# MKW38A4 register map
Vendor: NXP Semiconductors; Series: Kinetis_W; File version: 1.6
CPU: CM0PLUS r0p0, little endian, no MPU, no FPU, VTOR, 2 interrupt priority bits
Registers are 32-bit, read-write, no defined reset value unless marked. A register's access mark holds for its fields unless they carry their own. Offsets are from the block's base; [hi:lo] are bit positions; {n}, {i} and the like mark numbered series; 'fields as' and 'values as' point back to an identical list.

## SIM — System Integration Module
Base 0x40047000; register names take the prefix SIM_
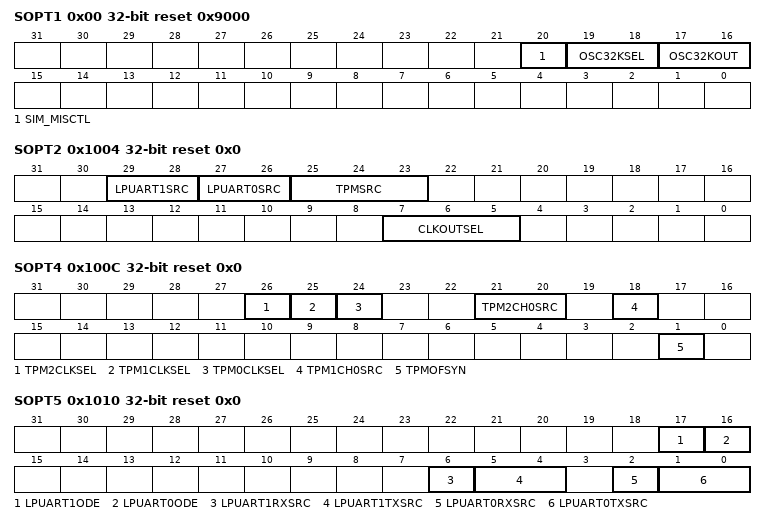
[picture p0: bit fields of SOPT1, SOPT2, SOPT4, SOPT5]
0x00 SOPT1 reset 0x9000 — System Options Register 1
  [20] SIM_MISCTL — This bit controls the function of BLE_RF_ACTIVE.
    0=Chip low power mode output to PAD; 1=Bluetooth LE active output to PAD
  [19:18] OSC32KSEL — 32K Oscillator Clock Select
    0=32kHz oscillator (OSC32KCLK); 2=RTC_CLKIN; 3=LPO 1kHz
  [17:16] OSC32KOUT — 32K oscillator clock output
    0=ERCLK32K is not output; 1=ERCLK32K is output on PTB3
0x1004 SOPT2 reset 0x0 — System Options Register 2
  [29:28] LPUART1SRC — LPUART1 Clock Source Select
    0=Clock disabled; 1=MCGFLLCLK clock; 2=OSCERCLK clock; 3=MCGIRCLK clock
  [27:26] LPUART0SRC — LPUART0 Clock Source Select
    values as LPUART1SRC
  [25:23] TPMSRC — TPM Clock Source Select
    0=Clock disabled; 1=MCGFLLCLK clock; 2=OSCERCLK clock; 3=MCGIRCLK clock; 4=LANT_SW
  [7:5] CLKOUTSEL — CLKOUT select
    0=OSCERCLK DIV2; 1=OSCERCLK DIV4; 2=Bus clock; 3=LPO clock 1 kHz; 4=MCGIRCLK; 5=OSCERCLK DIV8; 6=OSCERCLK
0x100C SOPT4 reset 0x0 — System Options Register 4
  [26] TPM2CLKSEL — TPM2 External Clock Pin Select
    0=TPM2 external clock driven by TPM_CLKIN0 pin; 1=TPM2 external clock driven by TPM_CLKIN1 pin
  [25] TPM1CLKSEL — TPM1 External Clock Pin Select
    0=TPM1 external clock driven by TPM_CLKIN0 pin; 1=TPM1 external clock driven by TPM_CLKIN1 pin
  [24] TPM0CLKSEL — TPM0 External Clock Pin Select
    0=TPM0 external clock driven by TPM_CLKIN0 pin; 1=TPM0 external clock driven by TPM_CLKIN1 pin
  [21:20] TPM2CH0SRC — TPM2 Channel 0 Input Capture Source Select
    0=TPM2_CH0 signal; 1=CMP0 output; 2=Radio time-of-flight timestamp trigger
  [18] TPM1CH0SRC — TPM1 Channel 0 Input Capture Source Select
    0=TPM1_CH0 signal; 1=CMP0 output
  [1] TPMOFSYN
    0=Enable TPM1 overflow output to TPM0 and TPM2 overflow in; 1=Disable TPM1 overflow output to TPM0 and TPM2 overflow in
0x1010 SOPT5 reset 0x0 — System Options Register 5
  [17] LPUART1ODE — LPUART1 Open Drain Enable
    0=Open drain is disabled on LPUART1; 1=Open drain is enabled on LPUART1
  [16] LPUART0ODE — LPUART0 Open Drain Enable
    0=Open drain is disabled on LPUART0; 1=Open drain is enabled on LPUART0
  [6] LPUART1RXSRC — LPUART1 Receive Data Source Select
    0=LPUART1_RX pin; 1=CMP0 output
  [5:4] LPUART1TXSRC — LPUART1 Transmit Data Source Select
    0=LPUART1_TX pin; 1=LPUART1_TX pin modulated with TPM1 channel 0 output; 2=LPUART1_TX pin modulated with TPM2 channel 0 output
  [2] LPUART0RXSRC — LPUART0 Receive Data Source Select
    0=LPUART_RX pin; 1=CMP0 output
  [1:0] LPUART0TXSRC — LPUART0 Transmit Data Source Select
    0=LPUART0_TX pin; 1=LPUART0_TX pin modulated with TPM1 channel 0 output; 2=LPUART0_TX pin modulated with TPM2 channel 0 output
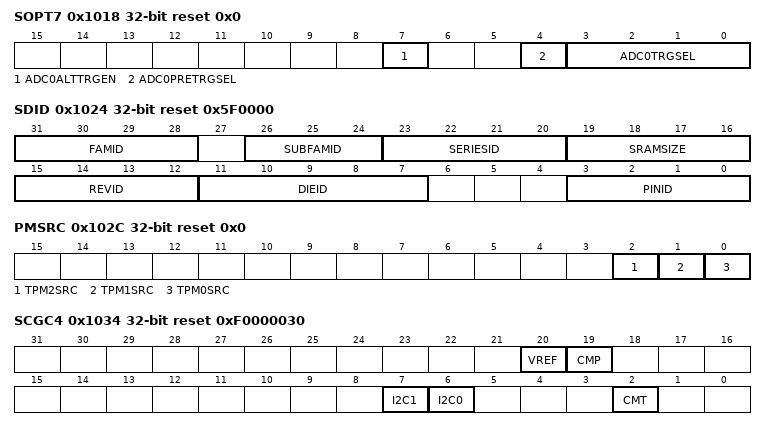
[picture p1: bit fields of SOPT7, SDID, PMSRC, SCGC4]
0x1018 SOPT7 reset 0x0 — System Options Register 7
  [7] ADC0ALTTRGEN — ADC0 Alternate Trigger Enable
    0=ADC ADHWT trigger comes from TPM1 channel 0 and channel1. Prior to the assertion of TPM1 channel 0, a pre-trigger pulse will be sent to ADHWTSA to initiate an ADC acquisition using ADCx_SC1A configuration and store ADC conversion in ADCx_RA Register. Prior to the assertion of TPM1 channel 1 a pre-trigger pulse will be sent to ADHWTSB to initiate an ADC acquisition using ADCx_SC1Bconfiguration and store ADC conversion in ADCx_RB Register.; 1=ADC ADHWT trigger comes from a peripheral event selected by ADC0TRGSEL bits.ADC0PRETRGSEL bit will select the optional ADHWTSA or ADHWTSB select lines for choosing the ADCx_SC1x config and ADCx_Rx result regsiter to store the ADC conversion
  [4] ADC0PRETRGSEL — ADC0 Pretrigger Select
    0=Pre-trigger ADHDWTSA is selected, thus ADC0 will use ADC0_SC1A configuration for the next ADC conversion and store the result in ADC0_RA register; 1=Pre-trigger ADHDWTSB is selected, thus ADC0 will use ADC0_SC1B configuration for the next ADC conversion and store the result in ADC0_RB register
  [3:0] ADC0TRGSEL — ADC0 Trigger Select
    0=External trigger pin input (EXTRG_IN); 1=CMP0 output; 4=PIT trigger 0; 5=PIT trigger 1; 8=TPM0 overflow; 9=TPM1 overflow; 10=TPM2 overflow; 12=RTC alarm interrupt and RTC seconds interrupt; 13=RTC seconds; 14=LPTMR0 trigger; 15=Radio TSM
0x1024 SDID ro reset 0x5F0000 — System Device Identification Register
  [31:28] FAMID — Kinetis family ID
    3=KW3x Family (BTLE)
  [26:24] SUBFAMID — Kinetis Sub-Family ID.
    7=KWx9 Sub family; 6=KWx7 Subfamily; 5=KWx8 Subfamily
  [23:20] SERIESID — Kinetis Series ID
    5=KW family
  [19:16] SRAMSIZE — System SRAM Size
    7=64 KB
  [15:12] REVID — Device Revision Number
  [11:7] DIEID — Device Die Number
  [3:0] PINID — Pin count Identification
    3=40-pin; 4=48-pin (LGA); 5=48-pin (wettable flank)
0x102C PMSRC reset 0x0 — Peripheral Module Soft Reset Control Register(SIM_PMSRC)
  [2] TPM2SRC wo — TPM2 Soft Reset Control
  [1] TPM1SRC wo — TPM1 Soft Reset Control
  [0] TPM0SRC wo — TPM0 Soft Reset Control
0x1034 SCGC4 reset 0xF0000030 — System Clock Gating Control Register 4
  [all] fields
    0=Clock disabled; 1=Clock enabled
  [20] VREF — VREF Clock Gate Control
  [19] CMP — Comparator Clock Gate Control
  [7] I2C1 — I2C1 Clock Gate Control
  [6] I2C0 — I2C0 Clock Gate Control
  [2] CMT — CMT Clock Gate Control
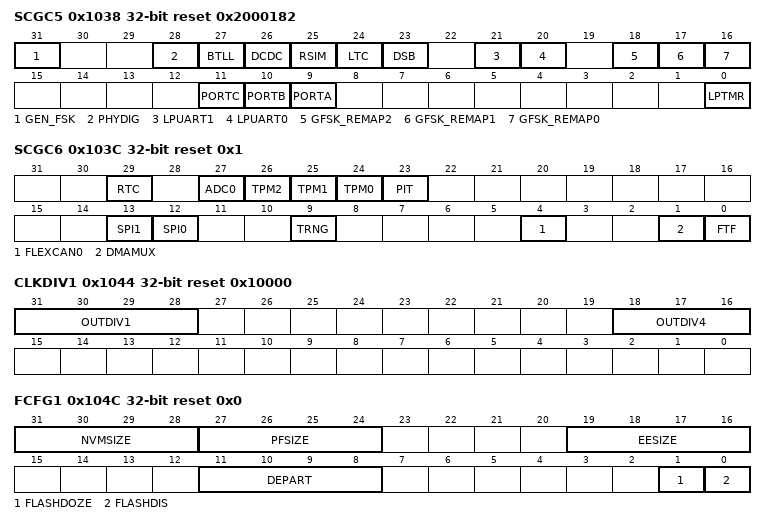
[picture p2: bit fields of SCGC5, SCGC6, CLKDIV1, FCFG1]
0x1038 SCGC5 reset 0x2000182 — System Clock Gating Control Register 5
  [31] GEN_FSK — Generic FSK enabled
    0=GFSK CGC bit disabled; 1=GFSK CGC bit enabled
  [28] PHYDIG — PHY Digital Clock Gate Control
    0=Clock disabled; 1=Clock enabled
  [27] BTLL — BTLL System Clock Gate Control
    0=Clock disabled; 1=Clock enabled
  [26] DCDC — DCDC Clock Gate Control
    0=Clock disabled; 1=Clock enabled
  [25] RSIM ro — RSIM Clock Gate Control
  [24] LTC — LTC Clock Gate Control
    0=Clock disabled; 1=Clock enabled
  [23] DSB — Data Stream Buffer Clock Gate Control
    0=Clock disabled; 1=Clock enabled
  [21] LPUART1 — LPUART1 Clock Gate Control
    0=Clock disabled; 1=Clock enabled
  [20] LPUART0 — LPUART0 Clock Gate Control
    0=Clock disabled; 1=Clock enabled
  [18] GFSK_REMAP2 — GFSK Remap2 Clock Gate Control
    0=Clock disabled; 1=Clock enabled
  [17] GFSK_REMAP1 — GFSK Remap1 Clock Gate Control
    0=Clock disabled; 1=Clock enabled
  [16] GFSK_REMAP0 — GFSK Remap0 Clock Gate Control
    0=Clock disabled; 1=Clock enabled
  [11] PORTC — Port C Clock Gate Control
    0=Clock disabled; 1=Clock enabled
  [10] PORTB — Port B Clock Gate Control
    0=Clock disabled; 1=Clock enabled
  [9] PORTA — Port A Clock Gate Control
    0=Clock disabled; 1=Clock enabled
  [0] LPTMR — Low Power Timer Access Control
    0=Access disabled; 1=Access enabled
0x103C SCGC6 reset 0x1 — System Clock Gating Control Register 6
  [29] RTC — RTC Access Control
    0=Access and interrupts disabled; 1=Access and interrupts enabled
  [27] ADC0 — ADC0 Clock Gate Control
    0=Clock disabled; 1=Clock enabled
  [26] TPM2 — TPM2 Clock Gate Control
    0=Clock disabled; 1=Clock enabled
  [25] TPM1 — TPM1 Clock Gate Control
    0=Clock disabled; 1=Clock enabled
  [24] TPM0 — TPM0 Clock Gate Control
    0=Clock disabled; 1=Clock enabled
  [23] PIT — PIT Clock Gate Control
    0=Clock disabled; 1=Clock enabled
  [13] SPI1 — SPI1 Clock Gate Control
    0=Clock disabled; 1=Clock enabled
  [12] SPI0 — SPI0 Clock Gate Control
    0=Clock disabled; 1=Clock enabled
  [9] TRNG — TRNG Clock Gate Control
    0=Clock disabled; 1=Clock enabled
  [4] FLEXCAN0 — FLEXCAN0 Clock Gate Control
    0=Clock disabled; 1=Clock enabled
  [1] DMAMUX — DMA Mux Clock Gate Control
    0=Clock disabled; 1=Clock enabled
  [0] FTF — Flash Memory Clock Gate Control
    0=Clock disabled; 1=Clock enabled
0x1040 SCGC7 reset 0x100 — System Clock Gating Control Register 7
  [8] DMA — DMA Clock Gate Control
    0=Clock disabled; 1=Clock enabled
0x1044 CLKDIV1 reset 0x10000 — System Clock Divider Register 1
  [31:28] OUTDIV1 — Clock 1 Output Divider value
    {v}=Divide-by-{v+1} (v=0..15)
  [18:16] OUTDIV4 — Clock 4 Output Divider value
    {v}=Divide-by-{v+1} (v=0..7)
0x104C FCFG1 reset 0x0 (reset mask 0xF0F0FF) — Flash Configuration Register 1
  [31:28] NVMSIZE ro — FlexNVM Size
    0=0 KB; 9=256 KB, 16 KB protection region; 15=256 KB, 16 KB protection region
  [27:24] PFSIZE ro — Program Flash Size
    9=256 KB of program flash memory; 11=512 KB of program flash memory
  [19:16] EESIZE ro — EEPROM Size
    1=8 KB; 2=4 KB; 3=2 KB; 4=1 KB; 5=512 bytes; 6=256 bytes; 7=128 bytes; 8=64 bytes; 9=32 bytes
  [11:8] DEPART ro — FlexNVM partition
  [1] FLASHDOZE
    0=Flash remains enabled during Doze mode; 1=Flash is disabled for the duration of Doze mode
  [0] FLASHDIS — Flash Disable
    0=Flash is enabled; 1=Flash is disabled
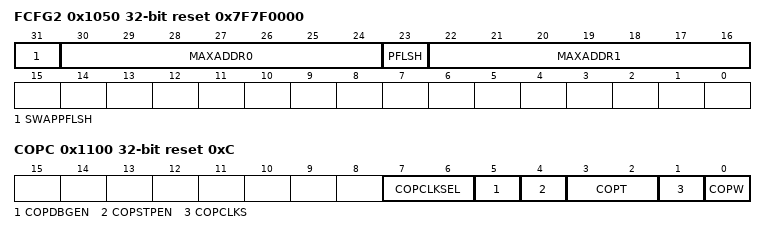
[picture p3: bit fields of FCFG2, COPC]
0x1050 FCFG2 ro reset 0x7F7F0000 — Flash Configuration Register 2
  [31] SWAPPFLSH — Swap program flash
    0=Swap is not active; 1=Swap is active
  [30:24] MAXADDR0 — Max Address block 0
  [23] PFLSH — Program flash only
    0=Device supports FlexNVM; 1=Program Flash only, device does not support FlexNVM
  [22:16] MAXADDR1 — This field concatenated with leading zeros plus the value of the MAXADDR1 field indicates the first invalid address of the second program flash block (flash block 1)
0x1058 UIDMH ro reset 0x0 — Unique Identification Register Mid-High
  [15:0] UID — Unique Identification
0x105C UIDML ro reset 0x0 — Unique Identification Register Mid Low
  [31:0] UID — Unique Identification
0x1060 UIDL ro reset 0x0 — Unique Identification Register Low
  [31:0] UID — Unique Identification
0x1100 COPC reset 0xC — COP Control Register
  [7:6] COPCLKSEL — COP Clock Select
    0=LPO clock (1 kHz); 1=MCGIRCLK; 2=OSCERCLK; 3=Bus clock
  [5] COPDBGEN — COP Debug Enable
    0=COP is disabled and the counter is reset in Debug mode; 1=COP is enabled in Debug mode
  [4] COPSTPEN — COP Stop Enable
    0=COP is disabled and the counter is reset in Stop modes; 1=COP is enabled in Stop modes
  [3:2] COPT — COP Watchdog Timeout
    0=COP disabled; 1=COP timeout after 25 cycles for short timeout or 213 cycles for long timeout; 2=COP timeout after 28 cycles for short timeout or 216 cycles for long timeout; 3=COP timeout after 210 cycles for short timeout or 218 cycles for long timeout
  [1] COPCLKS — COP Clock Select
    0=COP configured for short timeout; 1=COP configured for long timeout
  [0] COPW — COP Windowed Mode
    0=Normal mode; 1=Windowed mode
0x1104 SRVCOP wo reset 0x0 — Service COP
  [7:0] SRVCOP — Service COP Register
